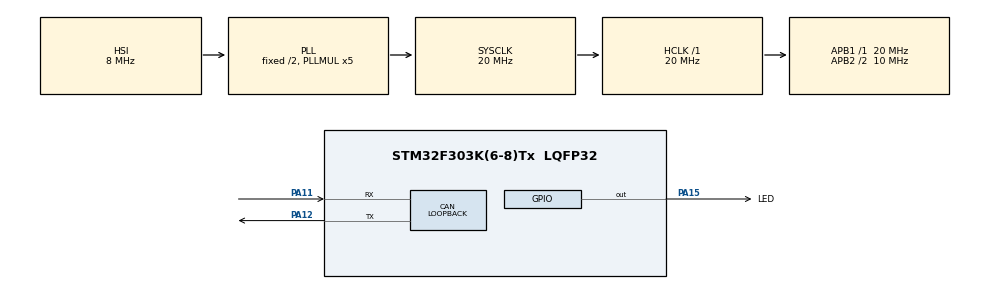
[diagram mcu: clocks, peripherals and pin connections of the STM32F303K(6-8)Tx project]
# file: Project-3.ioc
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CAN.BS1=CAN_BS1_5TQ
CAN.BS2=CAN_BS2_4TQ
CAN.CalculateTimeQuantum=800.0
CAN.Mode=CAN_MODE_LOOPBACK
Mcu.Family=STM32F3
Mcu.Name=STM32F303K(6-8)Tx
Mcu.Package=LQFP32
NVIC.CAN_RX0_IRQn=true\:0\:0\:false\:true\:true\:2\:true
NVIC.CAN_TX_IRQn=true\:0\:0\:false\:true\:true\:1\:true
NVIC.PriorityGroup=NVIC_PRIORITYGROUP_4
PA11.Mode=Master
PA11.Signal=CAN_RX
PA12.Mode=Master
PA12.Signal=CAN_TX
PA15.GPIO_Label=LED
PA15.Signal=GPIO_Output
ProjectManager.HeapSize=0x200
ProjectManager.StackSize=0x400
ProjectManager.TargetToolchain=MDK-ARM V5
RCC.AHBFreq_Value=20000000
RCC.APB1Freq_Value=20000000
RCC.APB1TimFreq_Value=20000000
RCC.APB2CLKDivider=RCC_HCLK_DIV2
RCC.APB2Freq_Value=10000000
RCC.APB2TimFreq_Value=20000000
RCC.CortexFreq_Value=20000000
RCC.HCLKFreq_Value=20000000
RCC.HSE_VALUE=8000000
RCC.HSI_VALUE=8000000
RCC.PLLMUL=RCC_PLL_MUL5
RCC.SYSCLKFreq_VALUE=20000000
RCC.SYSCLKSourceVirtual=RCC_SYSCLKSOURCE_PLLCLK
board=NUCLEO-F303K8

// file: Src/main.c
/**
  ******************************************************************************
  * @file           : main.c
  * @brief          : Main program body
  ******************************************************************************
  ** This notice applies to any and all portions of this file
  * that are not between comment pairs USER CODE BEGIN and
  * USER CODE END. Other portions of this file, whether
  * inserted by the user or by software development tools
  * are owned by their respective copyright owners.
  *
  * COPYRIGHT(c) 2019 STMicroelectronics
  *
  * Redistribution and use in source and binary forms, with or without modification,
  * are permitted provided that the following conditions are met:
  *   1. Redistributions of source code must retain the above copyright notice,
  *      this list of conditions and the following disclaimer.
  *   2. Redistributions in binary form must reproduce the above copyright notice,
  *      this list of conditions and the following disclaimer in the documentation
  *      and/or other materials provided with the distribution.
  *   3. Neither the name of STMicroelectronics nor the names of its contributors
  *      may be used to endorse or promote products derived from this software
  *      without specific prior written permission.
  *
  * THIS SOFTWARE IS PROVIDED BY THE COPYRIGHT HOLDERS AND CONTRIBUTORS "AS IS"
  * AND ANY EXPRESS OR IMPLIED WARRANTIES, INCLUDING, BUT NOT LIMITED TO, THE
  * IMPLIED WARRANTIES OF MERCHANTABILITY AND FITNESS FOR A PARTICULAR PURPOSE ARE
  * DISCLAIMED. IN NO EVENT SHALL THE COPYRIGHT HOLDER OR CONTRIBUTORS BE LIABLE
  * FOR ANY DIRECT, INDIRECT, INCIDENTAL, SPECIAL, EXEMPLARY, OR CONSEQUENTIAL
  * DAMAGES (INCLUDING, BUT NOT LIMITED TO, PROCUREMENT OF SUBSTITUTE GOODS OR
  * SERVICES; LOSS OF USE, DATA, OR PROFITS; OR BUSINESS INTERRUPTION) HOWEVER
  * CAUSED AND ON ANY THEORY OF LIABILITY, WHETHER IN CONTRACT, STRICT LIABILITY,
  * OR TORT (INCLUDING NEGLIGENCE OR OTHERWISE) ARISING IN ANY WAY OUT OF THE USE
  * OF THIS SOFTWARE, EVEN IF ADVISED OF THE POSSIBILITY OF SUCH DAMAGE.
  *
  ******************************************************************************
  */
#include "main.h"
#include "stm32f3xx_hal.h"
#include "stm32f3xx_it.h"

/* USER CODE BEGIN Includes */
CAN_HandleTypeDef hcan;

/* USER CODE END Includes */

CAN_HandleTypeDef hcan;

/* USER CODE BEGIN PV */
/* Private variables ---------------------------------------------------------*/
	CAN_HandleTypeDef hcan;
	CAN_FilterTypeDef MyFilterConfig;
	CAN_TxHeaderTypeDef DataTX;
	CAN_RxHeaderTypeDef DataRX;

	uint8_t DataTXmsg[4];
	uint8_t DataRXmsg[4];

	uint32_t MypTxMailbox;
/* USER CODE END PV */

void SystemClock_Config(void);
static void MX_GPIO_Init(void);
static void MX_CAN_Init(void);
static void MX_NVIC_Init(void);

/* USER CODE BEGIN PFP */
/* Private function prototypes -----------------------------------------------*/

/* USER CODE END PFP */

int main(void)
{

  /* MCU Configuration----------------------------------------------------------*/

  /* Reset of all peripherals, Initializes the Flash interface and the Systick. */
  HAL_Init();

  /* USER CODE BEGIN Init */
	DataTX.RTR = CAN_RTR_DATA;
	DataTX.TransmitGlobalTime = DISABLE;
	DataTX.IDE = CAN_ID_STD;
	DataTX.StdId = 0x0000;
	DataTX.DLC = 4;

	DataRX.IDE = CAN_ID_STD;
	DataRX.DLC = 4;

	MyFilterConfig.FilterIdLow = 0x0000;
	MyFilterConfig.FilterIdHigh = 0x0000;
	MyFilterConfig.FilterBank = 0;
	MyFilterConfig.FilterFIFOAssignment = CAN_FILTER_FIFO0;
	MyFilterConfig.FilterScale = CAN_FILTERSCALE_32BIT;
	MyFilterConfig.FilterMode = CAN_FILTERMODE_IDLIST;
	MyFilterConfig.FilterActivation = CAN_FILTER_ENABLE;

  /* USER CODE END Init */

  /* Configure the system clock */
  SystemClock_Config();

  /* Initialize all configured peripherals */
  MX_GPIO_Init();
  MX_CAN_Init();

  /* Initialize interrupts */
  MX_NVIC_Init();
  /* USER CODE BEGIN 2 */
	HAL_CAN_Init(&hcan);
	HAL_CAN_ConfigFilter(&hcan, &MyFilterConfig);

	HAL_CAN_Start(&hcan);
	HAL_CAN_ActivateNotification(&hcan, CAN_IT_TX_MAILBOX_EMPTY);
	HAL_CAN_ActivateNotification(&hcan, CAN_IT_RX_FIFO0_FULL);

	DataTXmsg[0] = 0x1F;
	DataTXmsg[1] = 0x2F;
	DataTXmsg[2] = 0x3F;
	DataTXmsg[3] = 0x4F;

	// We need to send 1 message to empty TxMailbox for interrupt
	HAL_CAN_AddTxMessage(&hcan, &DataTX, DataTXmsg, &MypTxMailbox);
  /* USER CODE END 2 */

  /* Infinite loop */
  /* USER CODE BEGIN WHILE */
  while (1)
  {

	//HAL_CAN_AddTxMessage(&hcan, &DataTX, DataTXmsg, &MypTxMailbox);
	//HAL_CAN_GetRxMessage(&hcan, 0, &DataRX, DataRXmsg);

	DataTXmsg[0] = 0x1F;
	DataTXmsg[1] = 0x2F;
	DataTXmsg[2] = 0x3F;
	DataTXmsg[3] = 0x4F;
  /* USER CODE END WHILE */

  }

}

void SystemClock_Config(void)
{

  RCC_OscInitTypeDef RCC_OscInitStruct;
  RCC_ClkInitTypeDef RCC_ClkInitStruct;

    /**Initializes the CPU, AHB and APB busses clocks
    */
  RCC_OscInitStruct.OscillatorType = RCC_OSCILLATORTYPE_HSI;
  RCC_OscInitStruct.HSIState = RCC_HSI_ON;
  RCC_OscInitStruct.HSICalibrationValue = 16;
  RCC_OscInitStruct.PLL.PLLState = RCC_PLL_ON;
  RCC_OscInitStruct.PLL.PLLSource = RCC_PLLSOURCE_HSI;
  RCC_OscInitStruct.PLL.PLLMUL = RCC_PLL_MUL5;
  if (HAL_RCC_OscConfig(&RCC_OscInitStruct) != HAL_OK)
  {
    _Error_Handler(__FILE__, __LINE__);
  }

    /**Initializes the CPU, AHB and APB busses clocks
    */
  RCC_ClkInitStruct.ClockType = RCC_CLOCKTYPE_HCLK|RCC_CLOCKTYPE_SYSCLK
                              |RCC_CLOCKTYPE_PCLK1|RCC_CLOCKTYPE_PCLK2;
  RCC_ClkInitStruct.SYSCLKSource = RCC_SYSCLKSOURCE_PLLCLK;
  RCC_ClkInitStruct.AHBCLKDivider = RCC_SYSCLK_DIV1;
  RCC_ClkInitStruct.APB1CLKDivider = RCC_HCLK_DIV1;
  RCC_ClkInitStruct.APB2CLKDivider = RCC_HCLK_DIV2;

  if (HAL_RCC_ClockConfig(&RCC_ClkInitStruct, FLASH_LATENCY_0) != HAL_OK)
  {
    _Error_Handler(__FILE__, __LINE__);
  }

    /**Configure the Systick interrupt time
    */
  HAL_SYSTICK_Config(HAL_RCC_GetHCLKFreq()/1000);

    /**Configure the Systick
    */
  HAL_SYSTICK_CLKSourceConfig(SYSTICK_CLKSOURCE_HCLK);

  /* SysTick_IRQn interrupt configuration */
  HAL_NVIC_SetPriority(SysTick_IRQn, 0, 0);
}

/**
  * @brief NVIC Configuration.
  * @retval None
  */
static void MX_NVIC_Init(void)
{
  /* CAN_TX_IRQn interrupt configuration */
  HAL_NVIC_SetPriority(CAN_TX_IRQn, 0, 0);
  HAL_NVIC_EnableIRQ(CAN_TX_IRQn);
  /* CAN_RX0_IRQn interrupt configuration */
  HAL_NVIC_SetPriority(CAN_RX0_IRQn, 0, 0);
  HAL_NVIC_EnableIRQ(CAN_RX0_IRQn);
}

/* CAN init function */
static void MX_CAN_Init(void)
{

  hcan.Instance = CAN;
  hcan.Init.Prescaler = 16;
  hcan.Init.Mode = CAN_MODE_LOOPBACK;
  hcan.Init.SyncJumpWidth = CAN_SJW_1TQ;
  hcan.Init.TimeSeg1 = CAN_BS1_5TQ;
  hcan.Init.TimeSeg2 = CAN_BS2_4TQ;
  hcan.Init.TimeTriggeredMode = DISABLE;
  hcan.Init.AutoBusOff = DISABLE;
  hcan.Init.AutoWakeUp = DISABLE;
  hcan.Init.AutoRetransmission = DISABLE;
  hcan.Init.ReceiveFifoLocked = DISABLE;
  hcan.Init.TransmitFifoPriority = DISABLE;
  if (HAL_CAN_Init(&hcan) != HAL_OK)
  {
    _Error_Handler(__FILE__, __LINE__);
  }

}

/** Configure pins as
        * Analog
        * Input
        * Output
        * EVENT_OUT
        * EXTI
*/
static void MX_GPIO_Init(void)
{

  GPIO_InitTypeDef GPIO_InitStruct;

  /* GPIO Ports Clock Enable */
  __HAL_RCC_GPIOA_CLK_ENABLE();

  /*Configure GPIO pin Output Level */
  HAL_GPIO_WritePin(LED_GPIO_Port, LED_Pin, GPIO_PIN_RESET);

  /*Configure GPIO pin : LED_Pin */
  GPIO_InitStruct.Pin = LED_Pin;
  GPIO_InitStruct.Mode = GPIO_MODE_OUTPUT_PP;
  GPIO_InitStruct.Pull = GPIO_NOPULL;
  GPIO_InitStruct.Speed = GPIO_SPEED_FREQ_LOW;
  HAL_GPIO_Init(LED_GPIO_Port, &GPIO_InitStruct);

}

void _Error_Handler(char *file, int line)
{
  while(1)
  {
  }
}

/************************ (C) COPYRIGHT STMicroelectronics *****END OF FILE****/
